# STM32U356 register map
File version: 1.0
CPU: CM33 r0p1, little endian, MPU, FPU, 4 interrupt priority bits
Registers are 32-bit, read-write, reset 0x0 unless marked. A register's access mark holds for its fields unless they carry their own. Offsets are from the block's base; [hi:lo] are bit positions; {n}, {i} and the like mark numbered series; 'fields as' and 'values as' point back to an identical list.

## EXTI — EXTI register block
Base 0x40032000
Same registers: SEC_EXTI 0x50032000
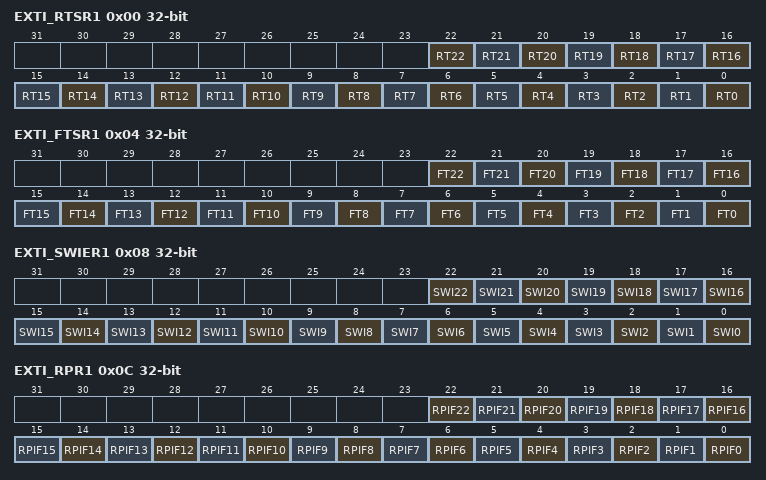
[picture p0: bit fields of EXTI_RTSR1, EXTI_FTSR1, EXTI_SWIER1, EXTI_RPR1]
0x00 EXTI_RTSR1 — EXTI rising trigger selection register
  [all] fields
    0=Rising trigger disabled (for event and interrupt) for input line; 1=Rising trigger enabled (for event and interrupt) for input line
  [n] RT{n} (n=0..22) — Rising trigger event configuration bit of configurable event input i
0x04 EXTI_FTSR1 — EXTI falling trigger selection register
  [all] fields
    0=Falling trigger disabled (for event and interrupt) for input line; 1=Falling trigger enabled (for event and interrupt) for input line
  [n] FT{n} (n=0..22) — Falling trigger event configuration bit of configurable event input i
0x08 EXTI_SWIER1 — EXTI software interrupt event register
  [all] fields
    0=Writing 0 has no effect; 1=Writing 1 triggers a rising edge event on event i
  [n] SWI{n} (n=0..22) — Software interrupt on event i
0x0C EXTI_RPR1 — EXTI rising edge pending register
  [all] fields
    0=No rising edge trigger request occurred; 1=Rising edge trigger request occurred
  [n] RPIF{n} (n=0..22) — Configurable event input i rising edge pending bit
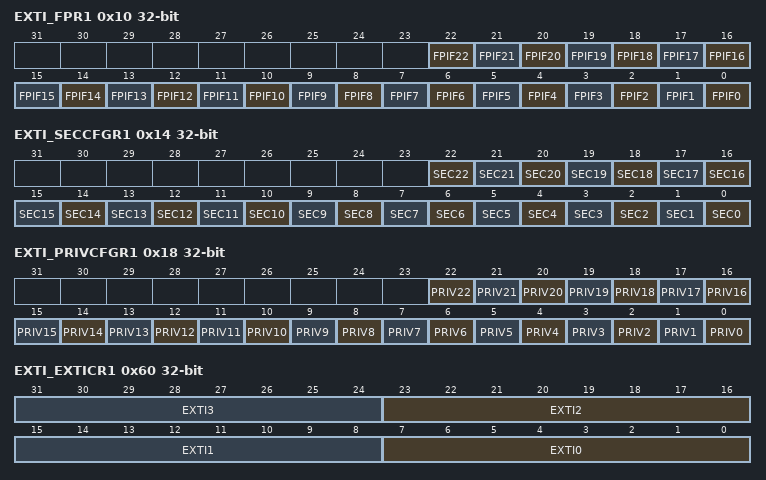
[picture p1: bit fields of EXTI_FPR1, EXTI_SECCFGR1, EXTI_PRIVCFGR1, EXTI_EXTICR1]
0x10 EXTI_FPR1 — EXTI falling edge pending register
  [all] fields
    0=No falling edge trigger request occurred; 1=Falling edge trigger request occurred
  [n] FPIF{n} (n=0..22) — configurable event inputs i falling edge pending bit
0x14 EXTI_SECCFGR1 — EXTI security configuration register
  [all] fields
    0=Event security disabled (nonsecure); 1=Event security enabled (secure)
  [n] SEC{n} (n=0..22) — Security enable on event input i
0x18 EXTI_PRIVCFGR1 — EXTI privilege configuration register
  [all] fields
    0=Event privilege disabled (unprivileged); 1=Event privilege enabled (privileged)
  [n] PRIV{n} (n=0..22) — Security enable on event input i
0x60 EXTI_EXTICR1 — EXTI external interrupt selection register
  [8n+7:8n] EXTI{n} (n=0..3) — EXTI{n} GPIO port selection
    0=PA[{n}] pin; 1=PB[{n}] pin; 2=PC[{n}] pin; 3=PD[{n}] pin; 4=PE[{n}] pin; 7=PH[{n}] pin
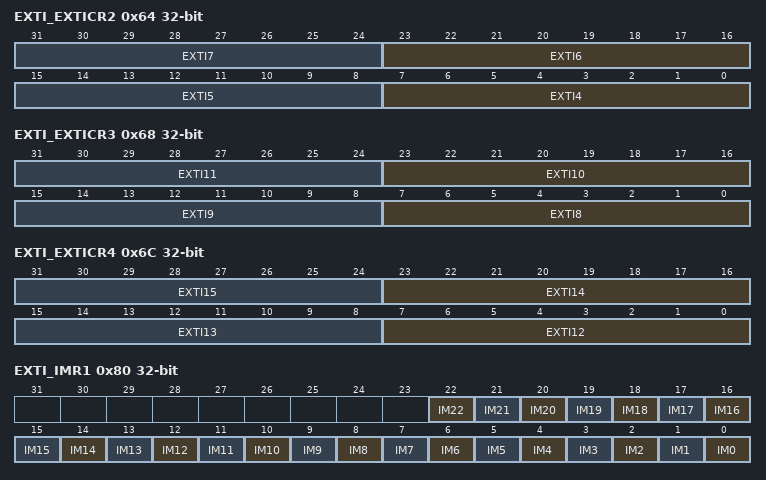
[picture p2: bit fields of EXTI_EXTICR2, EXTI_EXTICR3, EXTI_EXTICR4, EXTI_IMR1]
0x64 EXTI_EXTICR2 — EXTI external interrupt selection register
  [8n-25:8n-32] EXTI{n} (n=4..7) — EXTI{n} GPIO port selection
    values as EXTI_EXTICR1.EXTI0
0x68 EXTI_EXTICR3 — EXTI external interrupt selection register
  [8n-57:8n-64] EXTI{n} (n=8..11) — EXTI{n} GPIO port selection
    values as EXTI_EXTICR1.EXTI0
0x6C EXTI_EXTICR4 — EXTI external interrupt selection register
  [8n-89:8n-96] EXTI{n} (n=12..15) — EXTI{n} GPIO port selection
    values as EXTI_EXTICR1.EXTI0
0x70 EXTI_LOCKR — EXTI lock register
  [0] LOCK — Global security and privilege configuration registers (EXTI_SECCFGR and EXTI_PRIVCFGR) lock
    0=Security and privilege configuration open, can be modified; 1=Security and privilege configuration locked, can no longer be modified
0x80 EXTI_IMR1 — EXTI CPU wake-up with interrupt mask register
  [all] fields
    0=Wake-up with interrupt request from input event i is masked; 1=Wake-up with interrupt request from input event i is unmasked
  [n] IM{n} (n=0..22) — CPU wake-up with interrupt mask on event input i
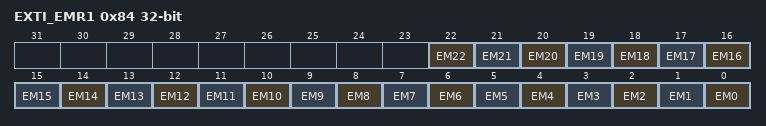
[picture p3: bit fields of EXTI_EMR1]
0x84 EXTI_EMR1 — EXTI CPU wake-up with event mask register
  [all] fields
    0=Wake-up with event generation from line i is masked; 1=Wake-up with event generation from line i is unmasked
  [n] EM{n} (n=0..22) — CPU wake-up with event generation mask on event input i

## GPIOA — GPIOA address block description
Base 0x42020000
Same registers: SEC_GPIOA 0x52020000
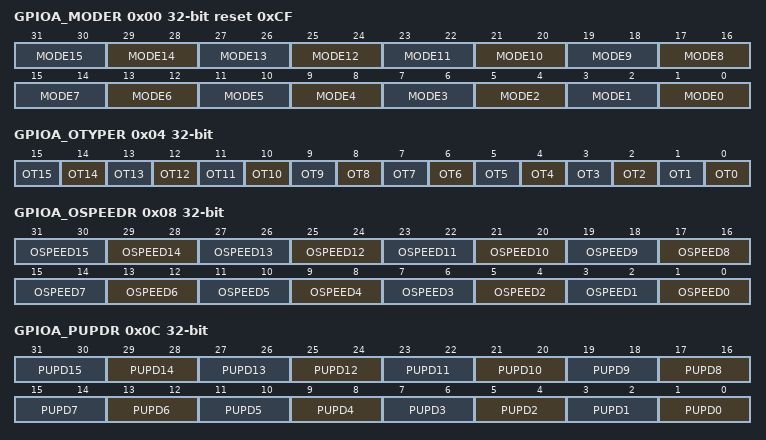
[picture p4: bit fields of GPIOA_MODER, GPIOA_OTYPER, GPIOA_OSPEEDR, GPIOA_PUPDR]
0x00 GPIOA_MODER reset 0xCF — GPIO port mode register
  [all] fields
    0=Input mode; 1=General purpose output mode; 2=Alternate function mode; 3=Analog mode (reset state)
  [2n+1:2n] MODE{n} (n=0..15) — Port x I/O pin y mode configuration
0x04 GPIOA_OTYPER — GPIO port output type register
  [all] fields
    0=Output push-pull (reset state); 1=Output open-drain
  [n] OT{n} (n=0..15) — Port x I/O pin y output type configuration
0x08 GPIOA_OSPEEDR — GPIO port output speed register
  [all] fields
    0=Low speed; 1=Medium speed; 2=High speed; 3=Very-high speed
  [2n+1:2n] OSPEED{n} (n=0..15) — Port x I/O pin y output speed configuration
0x0C GPIOA_PUPDR — GPIO port pull-up/pull-down register
  [all] fields
    0=No pull-up or pull-down; 1=Pull-up; 2=Pull-down
  [2n+1:2n] PUPD{n} (n=0..15) — Port x I/O pin y pull-up/pull-down configuration
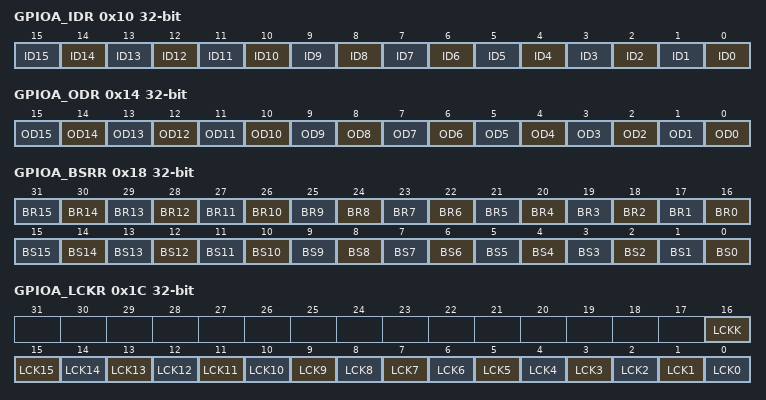
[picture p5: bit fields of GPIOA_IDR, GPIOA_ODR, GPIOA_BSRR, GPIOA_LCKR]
0x10 GPIOA_IDR ro (reset mask 0xFFFF0000) — GPIO port input data register
  [n] ID{n} (n=0..15) — Port x I/O pin y input data
0x14 GPIOA_ODR — GPIO port output data register
  [n] OD{n} (n=0..15) — Port x I/O pin y output data
0x18 GPIOA_BSRR wo — GPIO port bit set/reset register
  [n+16] BR{n} (n=0..15) — Port x I/O pin y output reset
    0=No action on the corresponding ODy bit; 1=Resets the corresponding ODy bit
  [n] BS{n} (n=0..15) — Port x I/O pin y output set
    0=No action on the corresponding ODy bit; 1=Sets the corresponding ODy bit
0x1C GPIOA_LCKR — GPIO port configuration lock register
  [16] LCKK — Lock key
    0=Port configuration lock key not active; 1=Port configuration lock key active
  [n] LCK{n} (n=0..15) — Port x I/O pin y lock
    0=Port configuration not locked; 1=Port configuration locked
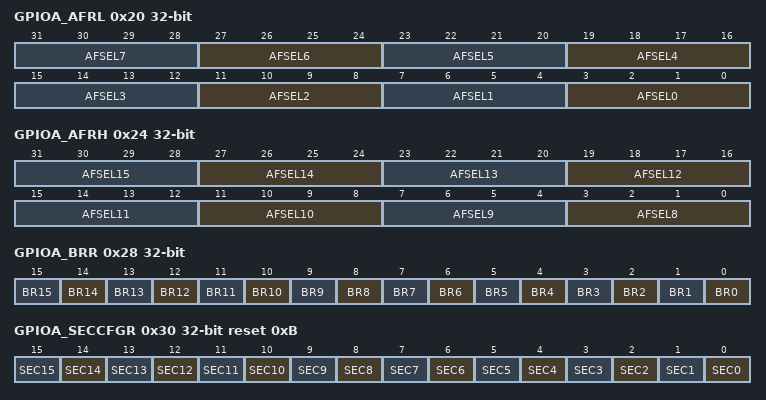
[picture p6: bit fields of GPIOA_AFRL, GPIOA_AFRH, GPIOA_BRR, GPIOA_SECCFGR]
0x20 GPIOA_AFRL — GPIO alternate function low register
  [all] fields
    {v}=AF{v} (v=0..15)
  [4n+3:4n] AFSEL{n} (n=0..7) — Port x I/O pin y alternate function selection for
0x24 GPIOA_AFRH — GPIO alternate function high register
  [all] fields
    {v}=AF{v} (v=0..15)
  [4n-29:4n-32] AFSEL{n} (n=8..15) — Port x I/O pin y alternate function selection
0x28 GPIOA_BRR wo — GPIO port bit reset register
  [all] fields
    0=No action on the corresponding ODy bit; 1=Reset the corresponding ODy bit
  [n] BR{n} (n=0..15) — Port x I/O pin y output reset
0x30 GPIOA_SECCFGR reset 0xB — GPIO secure configuration register
  [all] fields
    0=The I/O pin is nonsecure; 1=The I/O pin is secure
  [n] SEC{n} (n=0..15) — Port x I/O pin y security configuration

## GPIOB — GPIOB address block description
Base 0x42020400
Same registers: SEC_GPIOB 0x52020400
Registers as GPIOA (with GPIOA read as GPIOB).

## GPIOC — GPIOC address block description
Base 0x42020800
Same registers: SEC_GPIOC 0x52020800
Registers as GPIOA (with GPIOA read as GPIOC).

## GPIOD — GPIOD address block description
Base 0x42020C00
Same registers: SEC_GPIOD 0x52020C00
Registers as GPIOA (with GPIOA read as GPIOD).

## GPIOE — GPIOE address block description
Base 0x42021000
Same registers: SEC_GPIOE 0x52021000
Registers as GPIOA (with GPIOA read as GPIOE).

## GPIOH — GPIOH address block description
Base 0x42021C00
Same registers: SEC_GPIOH 0x52021C00
Registers as GPIOA (with GPIOA read as GPIOH).

## Notices in the file
Copyright (c) 2026 STMicroelectronics.
SPDx-License-Identifier: Apache-2.0
Licensed under the Apache License, Version 2.0 (the "License");
you may not use this file except in compliance with the License.
You may obtain a copy of the License at
http://www.apache.org/licenses/LICENSE-2.0
Unless required by applicable law or agreed to in writing, software
distributed under the License is distributed on an "AS IS" BASIS,
WITHOUT WARRANTIES OR CONDITIONS OF ANY KIND, either express or implied.
See the License for the specific language governing permissions and
limitations under the License.
